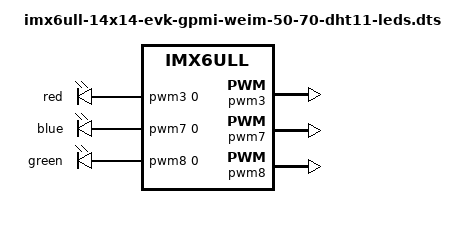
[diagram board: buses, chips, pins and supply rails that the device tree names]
/*
 * Copyright (C) 2016 Freescale Semiconductor, Inc.
 *
 * This program is free software; you can redistribute it and/or modify
 * it under the terms of the GNU General Public License version 2 as
 * published by the Free Software Foundation.
 */

#include "imx6ull-14x14-evk-gpmi-weim-50-70-dht11.dts"

/{

	pwm_leds{
		compatible = "pwm-leds";
		status = "okay";

		red {
			label = "red";
			active-low;
			pwms = <&pwm3 0 5000>;
			max-brightness = <255>;
		};

		blue {
			label =  "blue";
			active-low;
			pwms = <&pwm7 0 5000>;
			max-brightness = <255>;
		};

		green {
			label = "green";
			active-low;
			pwms = <&pwm8 0 5000>;
			max-brightness = <255>;
		};
	};

	ir_recv:ir-receiver {
			compatible = "gpio-ir-receiver";
			/*gpios = <&gpio1 1 GPIO_ACTIVE_LOW>;*/
			/*gpios = <&pinctrl_remote_control>;*/
			pinctrl-names = "default";
			pinctrl-0 = <&pinctrl_remote_control>;
			status = "okay";
	};
};

&csi {
	status = "disable";
	};


&i2c2 {
	ov5640: ov5640@3c {
		status = "disable";
		};
	};

&pwm3 {
	pinctrl-names = "default";
	pinctrl-0 = <&pinctrl_pwm3>;
	status = "okay";
};

&pwm7 {
	pinctrl-names = "default";
	pinctrl-0 = <&pinctrl_pwm7>;
	status = "okay";
};

&pwm8 {
	pinctrl-names = "default";
	pinctrl-0 = <&pinctrl_pwm8>;
	status = "okay";
};


&uart2{
	pinctrl-names = "default";
	pinctrl-0 = <&pinctrl_485>;
	fsl,rs485-gpio-txen = <&gpio1 18 GPIO_ACTIVE_HIGH>;
	linux,rs485-enabled-at-boot-time;
	status = "disable";
};
